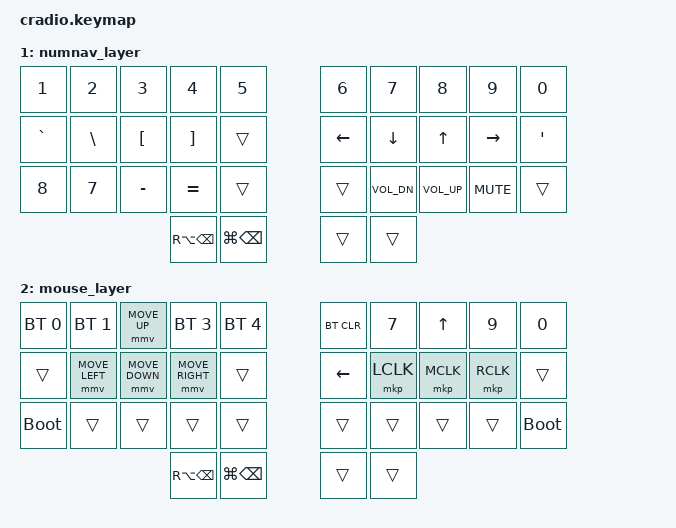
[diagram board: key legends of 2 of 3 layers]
// Copyright (c) 2022 The ZMK Contributors
// SPDX-License-Identifier: MIT
#define ZMK_POINTING_DEFAULT_MOVE_VAL 1500  // default: 600
#define ZMK_POINTING_DEFAULT_SCRL_VAL 20    // default: 10

#include <dt-bindings/zmk/pointing.h>
#include <behaviors.dtsi>
#include <dt-bindings/zmk/keys.h>
#include <dt-bindings/zmk/bt.h>

// Home row mods macros — per-finger behaviors (p=pinky, r=ring, m=mid, i=index)
#define HRML(k1,k2,k3,k4) &hml_p LCTRL k1  &hml_r LALT k2  &hml_m LGUI k3  &hml_i LSHFT k4
#define HRMR(k1,k2,k3,k4) &hmr_i RSHFT k1  &hmr_m RGUI k2  &hmr_r RALT k3  &hmr_p RCTRL k4

// Per-finger hold-tap timings (sunaku: https://sunaku.github.io/home-row-mods.html)
// Base TAPPING_RESOLUTION = 180ms; holding time = base + finger offset
#define HM_PINKY_TIME  300  // +120ms — slowest, most deliberate
#define HM_RINGY_TIME  300  // +120ms — bumped to give ring→pinky rolls more room
#define HM_RINGY_R_TIME 450  // right ring: extra-high to prevent io roll misfire (never need Alt+O same hand)
#define HM_RINGY_R_IDLE 350  // right ring: higher idle suppresses hold during typing streaks
#define HM_MIDDY_TIME  280  // +80ms
#define HM_INDEX_TIME  260  // +60ms
#define HM_STREAK      220  // require-prior-idle: suppress mods during typing streaks
#define HM_REPEAT      330  // quick-tap: hold-after-tap auto-repeat window

// Bilateral key position groups
#define LEFT_KEYS  0 1 2 3 4 10 11 12 13 14 20 21 22 23 24
#define RIGHT_KEYS 5 6 7 8 9 15 16 17 18 19 25 26 27 28 29
#define THUMB_KEYS 30 31 32 33

/ {
    behaviors {
        ht: hold_tap {
            compatible = "zmk,behavior-hold-tap";
            #binding-cells = <2>;
            flavor = "tap-preferred";
            tapping-term-ms = <280>;
            quick-tap-ms = <150>;
            require-prior-idle-ms = <180>;
            bindings = <&kp>, <&kp>;
        };
        hml_p: hm_left_pinky {
            compatible = "zmk,behavior-hold-tap";
            #binding-cells = <2>;
            flavor = "tap-preferred";
            tapping-term-ms = <HM_PINKY_TIME>;
            quick-tap-ms = <HM_REPEAT>;
            require-prior-idle-ms = <HM_STREAK>;
            bindings = <&kp>, <&kp>;
            hold-trigger-on-release;
            hold-trigger-key-positions = <RIGHT_KEYS THUMB_KEYS>;
        };
        hml_r: hm_left_ringy {
            compatible = "zmk,behavior-hold-tap";
            #binding-cells = <2>;
            flavor = "tap-preferred";
            tapping-term-ms = <HM_RINGY_TIME>;
            quick-tap-ms = <HM_REPEAT>;
            require-prior-idle-ms = <HM_STREAK>;
            bindings = <&kp>, <&kp>;
            hold-trigger-on-release;
            hold-trigger-key-positions = <RIGHT_KEYS THUMB_KEYS>;
        };
        hml_m: hm_left_middy {
            compatible = "zmk,behavior-hold-tap";
            #binding-cells = <2>;
            flavor = "tap-preferred";
            tapping-term-ms = <HM_MIDDY_TIME>;
            quick-tap-ms = <HM_REPEAT>;
            require-prior-idle-ms = <HM_STREAK>;
            bindings = <&kp>, <&kp>;
            hold-trigger-on-release;
            hold-trigger-key-positions = <RIGHT_KEYS THUMB_KEYS>;
        };
        hml_i: hm_left_index {
            compatible = "zmk,behavior-hold-tap";
            #binding-cells = <2>;
            flavor = "tap-preferred";
            tapping-term-ms = <HM_INDEX_TIME>;
            quick-tap-ms = <HM_REPEAT>;
            require-prior-idle-ms = <HM_STREAK>;
            bindings = <&kp>, <&kp>;
            hold-trigger-on-release;
            hold-trigger-key-positions = <RIGHT_KEYS THUMB_KEYS>;
        };
        hmr_p: hm_right_pinky {
            compatible = "zmk,behavior-hold-tap";
            #binding-cells = <2>;
            flavor = "tap-preferred";
            tapping-term-ms = <HM_PINKY_TIME>;
            quick-tap-ms = <HM_REPEAT>;
            require-prior-idle-ms = <HM_STREAK>;
            bindings = <&kp>, <&kp>;
            hold-trigger-on-release;
            hold-trigger-key-positions = <LEFT_KEYS THUMB_KEYS>;
        };
        hmr_r: hm_right_ringy {
            compatible = "zmk,behavior-hold-tap";
            #binding-cells = <2>;
            flavor = "tap-preferred";
            tapping-term-ms = <HM_RINGY_R_TIME>;
            quick-tap-ms = <HM_REPEAT>;
            require-prior-idle-ms = <HM_RINGY_R_IDLE>;
            bindings = <&kp>, <&kp>;
            hold-trigger-on-release;
            hold-trigger-key-positions = <LEFT_KEYS THUMB_KEYS>;
        };
        hmr_m: hm_right_middy {
            compatible = "zmk,behavior-hold-tap";
            #binding-cells = <2>;
            flavor = "tap-preferred";
            tapping-term-ms = <HM_MIDDY_TIME>;
            quick-tap-ms = <HM_REPEAT>;
            require-prior-idle-ms = <HM_STREAK>;
            bindings = <&kp>, <&kp>;
            hold-trigger-on-release;
            hold-trigger-key-positions = <LEFT_KEYS THUMB_KEYS>;
        };
        hmr_i: hm_right_index {
            compatible = "zmk,behavior-hold-tap";
            #binding-cells = <2>;
            flavor = "tap-preferred";
            tapping-term-ms = <HM_INDEX_TIME>;
            quick-tap-ms = <HM_REPEAT>;
            require-prior-idle-ms = <HM_STREAK>;
            bindings = <&kp>, <&kp>;
            hold-trigger-on-release;
            hold-trigger-key-positions = <LEFT_KEYS THUMB_KEYS>;
        };
        lt_thumb: layer_tap_thumb {
            compatible = "zmk,behavior-hold-tap";
            #binding-cells = <2>;
            flavor = "balanced";
            tapping-term-ms = <280>;
            quick-tap-ms = <HM_REPEAT>;
            bindings = <&mo>, <&kp>;
        };
        mmv: mouse_move {
            compatible = "zmk,behavior-input-two-axis";
            #binding-cells = <1>;
            x-input-code = <INPUT_REL_X>;
            y-input-code = <INPUT_REL_Y>;
            time-to-max-speed-ms = <100>;
            acceleration-exponent = <1>;
        };
    };
    combos {
      compatible = "zmk,combos";
        combo_tab {
            timeout-ms = <30>;
            require-prior-idle-ms = <100>;
            key-positions = <10 11>;
            bindings = <&kp TAB>;
        };
        combo_grave {
            timeout-ms = <30>;
            require-prior-idle-ms = <100>;
            key-positions = <2 12>;
            bindings = <&kp GRAVE>;
        };
        combo_escape {
            timeout-ms = <30>;
            require-prior-idle-ms = <100>;
            key-positions = <11 12>;
            bindings = <&kp ESC>;
        };
        combo_quote {
            timeout-ms = <50>;
            require-prior-idle-ms = <100>;
            key-positions = <9 19>;
            bindings = <&kp SQT>;
        };
        combo_backspace {
            timeout-ms = <30>;
            require-prior-idle-ms = <100>;
            key-positions = <6 7>;
            bindings = <&kp BSPC>;
        };
        combo_return {
            timeout-ms = <30>;
            require-prior-idle-ms = <100>;
            key-positions = <7 8>;
            bindings = <&kp ENTER>;
        };
        combo_dash {
            timeout-ms = <30>;
            require-prior-idle-ms = <100>;
            key-positions = <17 27>;
            bindings = <&kp MINUS>;
        };
        combo_b {
            timeout-ms = <30>;
            require-prior-idle-ms = <100>;
            key-positions = <3 13>;
            bindings = <&kp B>;
        };
        combo_g {
            timeout-ms = <30>;
            require-prior-idle-ms = <100>;
            key-positions = <13 14>;
            bindings = <&kp G>;
        };
        combo_v {
            timeout-ms = <30>;
            require-prior-idle-ms = <100>;
            key-positions = <13 23>;
            bindings = <&kp V>;
        };
        combo_j {
            timeout-ms = <30>;
            require-prior-idle-ms = <100>;
            key-positions = <6 16>;
            bindings = <&kp J>;
        };
        combo_m {
            timeout-ms = <30>;
            require-prior-idle-ms = <100>;
            key-positions = <15 16>;
            bindings = <&kp M>;
        };
        combo_k {
            timeout-ms = <30>;
            require-prior-idle-ms = <100>;
            key-positions = <16 26>;
            bindings = <&kp K>;
        };
    };


    keymap {
        compatible = "zmk,keymap";
        default_layer {
            bindings = <
        //╭──────────┬──────────┬──────────┬──────────┬──────────╮   ╭──────────┬──────────┬──────────┬──────────┬──────────╮
        //│  Q       │  W       │  F       │  P       │  B       │   │  J       │  L       │  U       │  Y       │  ;       │
            &kp Q      &kp W      &kp F      &kp P      &kp B          &kp J      &kp L      &kp U      &kp Y      &kp SEMI
        //├──────────┼──────────┼──────────┼──────────┼──────────┤   ├──────────┼──────────┼──────────┼──────────┼──────────┤
        //│  A       │  R       │  S       │  T       │  G       │   │  M       │  N       │  E       │  I       │   O      │
             HRML(A,        R,         S,          T)      &kp G          &kp M    HRMR( N,        E,          I,          O)
        //├──────────┼──────────┼──────────┼──────────┼──────────┤   ├──────────┼──────────┼──────────┼──────────┼──────────┤
        //│  Z       │  X       │  C       │  D       │  V       │   │  K       │  H       │ , <      │ . >      │ / ?      │
            &kp Z       &kp X      &kp C      &kp D      &kp V          &kp K      &kp H    &kp COMMA   &kp DOT   &kp FSLH
        //╰──────────┴──────────┴──────────┼──────────┼──────────┤   ├──────────┼──────────┼──────────┴──────────┴──────────╯
                                      &mt LSFT BSPC  &mt LGUI TAB     &lt_thumb 2 ENTER   &lt_thumb 1 SPACE
        //                                 ╰──────────┴──────────╯   ╰──────────┴──────────╯
            >;
        };

        numnav_layer {
            bindings = <
        //╭──────────┬──────────┬──────────┬──────────┬──────────╮   ╭──────────┬──────────┬──────────┬──────────┬──────────╮
        //│     1    │     2    │    3     │    4     │    5     │   │    6     │     7    │    8     │     9    │    0     │
            &kp N1     &kp N2      &kp N3     &kp N4     &kp N5         &kp N6     &kp N7     &kp N8     &kp N9    &kp N0
        //├──────────┼──────────┼──────────┼──────────┼──────────┤   ├──────────┼──────────┼──────────┼──────────┼──────────┤
        //│    `     │    \     │    [     │    ]     │          │   │ LEFT     │ DOWN     │ UP       │ RIGHT    │  '"      │
            &kp GRAVE  &kp BSLH    &kp LBKT  &kp RBKT    &trans        &kp LEFT   &kp DOWN   &kp UP   &kp RIGHT   &kp SQT
        //├──────────┼──────────┼──────────┼──────────┼──────────┤   ├──────────┼──────────┼──────────┼──────────┼──────────┤
        //│          │          │    -     │    =     │          │   │          │          │          │          │          │
          &kp N8       &kp N7     &kp MINUS   &kp EQUAL   &trans         &trans  &kp C_VOL_DN &kp C_VOL_UP &kp C_MUTE &trans
        //╰──────────┴──────────┴──────────┼──────────┼──────────┤   ├──────────┼──────────┼──────────┴──────────┴──────────╯
                                          &kp RA(BSPC) &kp LG(BSPC)     &trans    &trans
        //                                 ╰──────────┴──────────╯   ╰──────────┴──────────╯
            >;
        };
        mouse_layer {
            bindings = <
        //╭──────────┬──────────┬──────────┬──────────┬──────────╮   ╭──────────┬──────────┬──────────┬──────────┬──────────╮
        //│     1    │     2    │  m up    │    4     │    5     │   │    6     │     7    │    up    │     9    │    0     │
     &bt BT_SEL 0 &bt BT_SEL 1 &mmv MOVE_UP &bt BT_SEL 3 &bt BT_SEL 4 &bt BT_CLR    &kp N7     &kp UP     &kp N9    &kp N0
        //├──────────┼──────────┼──────────┼──────────┼──────────┤   ├──────────┼──────────┼──────────┼──────────┼──────────┤
        //│          │  m left  │  m down  │  m right │          │   │   LEFT   │ l_click  │  m_click │ r_click  │          │
      &trans &mmv MOVE_LEFT &mmv MOVE_DOWN &mmv MOVE_RIGHT &trans     &kp LEFT   &mkp LCLK  &mkp MCLK  &mkp RCLK   &trans
        //├──────────┼──────────┼──────────┼──────────┼──────────┤   ├──────────┼──────────┼──────────┼──────────┼──────────┤
        //│          │          │          │          │          │   │          │          │          │          │          │
          &bootloader &trans     &trans      &trans     &trans          &trans     &trans     &trans     &trans   &bootloader
        //╰──────────┴──────────┴──────────┼──────────┼──────────┤   ├──────────┼──────────┼──────────┴──────────┴──────────╯
                                          &kp RA(BSPC) &kp LG(BSPC)     &trans     &trans
        //                                 ╰──────────┴──────────╯   ╰──────────┴──────────╯
            >;
        };
    };
};
